# TESTCHIP register map
Vendor: TestVendor; Series: TEST; File version: 1.0
Test chip for unit testing
CPU: CM4 r1p0, little endian, MPU, FPU, 4 interrupt priority bits
Registers are 32-bit, read-only, reset 0x0 unless marked. A register's access mark holds for its fields unless they carry their own. Offsets are from the block's base; lines under a group give offsets from that group; [hi:lo] are bit positions; {n}, {i} and the like mark numbered series; 'fields as' and 'values as' point back to an identical list; <NAME> marks a mode.

## Memory map
0x40000000 TIMER0 size 0x400 — General-purpose timer
0x40001000 TIMER1 size 0x400
0x50000000 GPIO size 0x400 — General-purpose I/O

## Interrupts
10 TIMER0_IRQ (TIMER0) — TIMER0 interrupt
11 TIMER1_IRQ (TIMER1) — TIMER1 interrupt

## TIMER0 — General-purpose timer
Base 0x40000000
Same registers: TIMER1 0x40001000
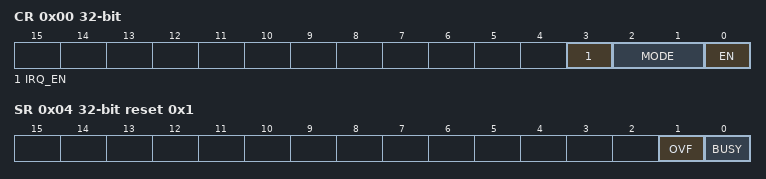
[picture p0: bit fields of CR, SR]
0x00 CR rw — Control register
  [3] IRQ_EN — Interrupt enable
  [2:1] MODE — Timer mode
  [0] EN — Timer enable
0x04 SR reset 0x1 — Status register
  [1] OVF — Overflow flag
  [0] BUSY — Timer busy
0x08 CNT — Counter value
